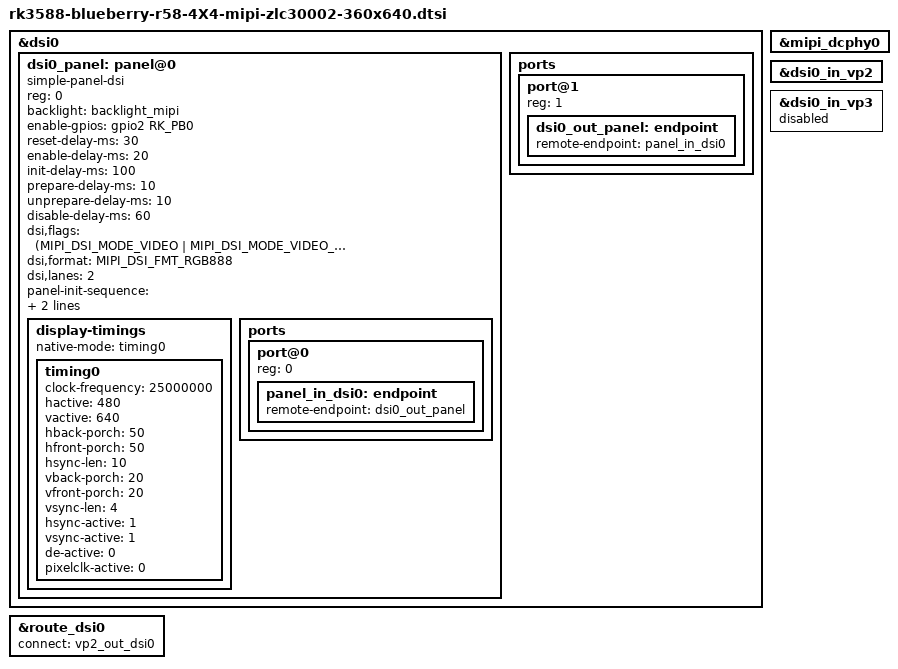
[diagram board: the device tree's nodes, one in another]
// SPDX-License-Identifier: (GPL-2.0+ OR MIT)
/*
 * Copyright (c) 2021 Rockchip Electronics Co., Ltd.
 *
 */

#include "dt-bindings/usb/pd.h"



&dsi0 {
	status = "okay";
	//rockchip,lane-rate = <1000>;
	dsi0_panel: panel@0 {
		status = "okay";
		compatible = "simple-panel-dsi";
		reg = <0>;
		backlight = <&backlight_mipi>;
		//power-supply = <&vcc3v3_mipi_lcd_power>;
		//reset-gpios =  <&gpio3 RK_PC4 GPIO_ACTIVE_LOW>; 
		enable-gpios = <&gpio2 RK_PB0 GPIO_ACTIVE_HIGH>;
		reset-delay-ms = <30>;
		enable-delay-ms = <20>;
		init-delay-ms = <100>;
		prepare-delay-ms = <10>;
		unprepare-delay-ms = <10>;
		disable-delay-ms = <60>;
		dsi,flags = <(MIPI_DSI_MODE_VIDEO | MIPI_DSI_MODE_VIDEO_BURST |
			MIPI_DSI_MODE_LPM | MIPI_DSI_MODE_EOT_PACKET)>;
		dsi,format = <MIPI_DSI_FMT_RGB888>;
		dsi,lanes  = <2>;

		panel-init-sequence = [
			29 00 06 FF 77 01 00 00 13
			29 00 03 E8 00 0E
			29 00 06 FF 77 01 00 00 00
			05 78 01 11
			29 00 06 FF 77 01 00 00 13
			29 0A 03 E8 00 0C
			29 00 03 E8 00 00
			29 00 06 FF 77 01 00 00 00
			29 00 06 FF 77 01 00 00 10
			29 00 03 C0 4F 00
			29 00 03 C1 07 02
			29 00 03 C2 31 05
			23 00 02 C6 01
			23 00 02 CC 38
			29 00 11 B0 00 0A 11 0C 10 05 00 08 08 1F 07 13 10 A9 30 18
			29 00 11 B1 00 0B 11 0D 0F 05 02 07 06 20 05 15 13 A9 30 18
			29 00 06 FF 77 01 00 00 11
			23 00 02 B0 53
			23 00 02 B1 60
			23 00 02 B2 87
			23 00 02 B3 80
			23 00 02 B5 49
			23 00 02 B7 85
			23 00 02 B8 21
			23 00 02 C1 78
			23 78 02 C2 78
			29 00 04 E0 00 00 02
			29 00 0C E1 03 A0 00 00 02 A0 00 00 00 33 33
			29 00 0D E2 22 22 33 33 88 A0 00 00 87 A0 00 00
			29 00 05 E3 00 00 22 22
			29 00 03 E4 44 44
			29 00 11 E5 04 84 A0 A0 06 86 A0 A0 08 88 A0 A0 0A 8A A0 A0
			29 00 05 E6 00 00 22 22
			29 00 03 E7 44 44
			29 00 11 E8 03 83 A0 A0 05 85 A0 A0 07 87 A0 A0 09 89 A0 A0
			29 00 08 EB 00 01 E4 E4 88 00 40
			29 00 03 EC 3C 01
			29 00 11 ED AB 89 76 54 02 FF FF FF FF FF FF 20 45 67 98 BA
			29 00 07 EF 08 08 08 08 3F 1F
			29 00 06 FF 77 01 00 00 00
			05 14 01 29
		];
		
/*
		panel-init-sequence = [
			29 00 06 FF 77 01 00 00 13
			29 00 03 E8 00 0E
			29 00 06 FF 77 01 00 00 00
			05 78 01 11
			29 00 06 FF 77 01 00 00 13
			29 0A 03 E8 00 0C
			29 00 03 E8 00 00
			29 00 06 FF 77 01 00 00 00
			29 00 06 FF 77 01 00 00 10
			29 00 03 C0 4F 00
			29 00 03 C1 07 02
			29 00 03 C2 31 05
			23 00 02 C6 01
			23 00 02 CC 38
			29 00 11 B0 00 0A 11 0C 10 05 00 08 08 1F 07 13 10 A9 30 18
			29 00 11 B1 00 0B 11 0D 0F 05 02 07 06 20 05 15 13 A9 30 18
			29 00 06 FF 77 01 00 00 11
			23 00 02 B0 53
			23 00 02 B1 60
			23 00 02 B2 87
			23 00 02 B3 80
			23 00 02 B5 49
			23 00 02 B7 85
			23 00 02 B8 21
			23 00 02 C1 78
			23 78 02 C2 78
			29 00 04 E0 00 00 02
			29 00 0C E1 03 A0 00 00 02 A0 00 00 00 33 33
			29 00 0D E2 22 22 33 33 88 A0 00 00 87 A0 00 00
			29 00 05 E3 00 00 22 22
			29 00 03 E4 44 44
			29 00 11 E5 04 84 A0 A0 06 86 A0 A0 08 88 A0 A0 0A 8A A0 A0
			29 00 05 E6 00 00 22 22
			29 00 03 E7 44 44
			29 00 11 E8 03 83 A0 A0 05 85 A0 A0 07 87 A0 A0 09 89 A0 A0
			29 00 08 EB 00 01 E4 E4 88 00 40
			29 00 03 EC 3C 01
			29 00 11 ED AB 89 76 54 02 FF FF FF FF FF FF 20 45 67 98 BA
			29 00 07 EF 08 08 08 08 3F 1F
			29 00 06 FF 77 01 00 00 00
			05 14 01 29
		];
*/
		panel-exit-sequence = [
		];

		display-timings {
			native-mode = <&timing0>;
			/*timing0: timing0 {
				clock-frequency = <25000000>;  //159391260  159747840
				hactive = <480>;
				vactive = <640>; 
				hback-porch = <20>;
				hfront-porch = <10>;
				hsync-len = <4>;
				vback-porch = <14>;
				vfront-porch = <8>;
				vsync-len = <4>;
				hsync-active = <1>;
				vsync-active = <1>;
				de-active = <0>;
				pixelclk-active = <0>;
				};*/

				timing0: timing0 {
				clock-frequency = <25000000>;  //159391260  159747840
				hactive = <480>;
				vactive = <640>; 
				hback-porch = <50>;
				hfront-porch = <50>;
				hsync-len = <10>;
				vback-porch = <20>;
				vfront-porch = <20>;
				vsync-len = <4>;
				hsync-active = <1>;
				vsync-active = <1>;
				de-active = <0>;
				pixelclk-active = <0>;
				};
				
			/*timing0: timing0 {
				clock-frequency = <35000000>;  //159391260  159747840
				hactive = <360>;
				vactive = <640>; 
				hback-porch = <50>;
				hfront-porch = <10>;
				hsync-len = <8>;
				vback-porch = <11>;
				vfront-porch = <2>;
				vsync-len = <8>;
				hsync-active = <1>;
				vsync-active = <1>;
				de-active = <0>;
				pixelclk-active = <0>;
				};*/
		};

		ports {
			#address-cells = <1>;
			#size-cells = <0>;

			port@0 {
				reg = <0>;
				panel_in_dsi0: endpoint {
					remote-endpoint = <&dsi0_out_panel>;
				};
			};
		};
	};

		ports {
			#address-cells = <1>;
			#size-cells = <0>;

			port@1 {
				reg = <1>;
				dsi0_out_panel: endpoint {
					remote-endpoint = <&panel_in_dsi0>;
				};
			};
		};
	
};

&dsi0 {
	status = "okay";
};

&mipi_dcphy0 {
	status = "okay";
};

&dsi0_in_vp2 {
	status = "okay";
};

&dsi0_in_vp3 {
	status = "disabled";
};

&route_dsi0 {
	status = "okay";
	connect = <&vp2_out_dsi0>;
};
